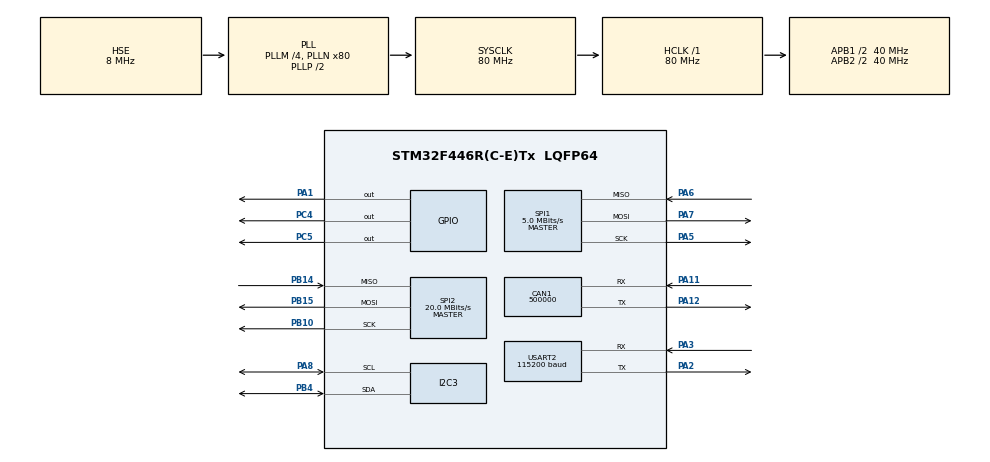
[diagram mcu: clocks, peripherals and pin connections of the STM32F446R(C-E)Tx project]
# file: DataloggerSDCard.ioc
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CAN1.BS1=CAN_BS1_3TQ
CAN1.CalculateBaudRate=500000
CAN1.CalculateTimeBit=2000
CAN1.CalculateTimeQuantum=400.0
CAN1.Mode=CAN_MODE_LOOPBACK
FATFS._MAX_SS=4096
FATFS._USE_LFN=1
Mcu.Family=STM32F4
Mcu.Name=STM32F446R(C-E)Tx
Mcu.Package=LQFP64
NVIC.CAN1_RX0_IRQn=true\:0\:0\:false\:false\:true\:true\:true\:true
NVIC.CAN1_RX1_IRQn=true\:0\:0\:false\:false\:true\:true\:true\:true
NVIC.PriorityGroup=NVIC_PRIORITYGROUP_4
PA1.Signal=GPIO_Output
PA11.Mode=CAN_Activate
PA11.Signal=CAN1_RX
PA12.Mode=CAN_Activate
PA12.Signal=CAN1_TX
PA2.Mode=Asynchronous
PA2.Signal=USART2_TX
PA3.Mode=Asynchronous
PA3.Signal=USART2_RX
PA5.Mode=Full_Duplex_Master
PA5.Signal=SPI1_SCK
PA6.Mode=Full_Duplex_Master
PA6.Signal=SPI1_MISO
PA7.Mode=Full_Duplex_Master
PA7.Signal=SPI1_MOSI
PA8.Mode=I2C
PA8.Signal=I2C3_SCL
PB10.Mode=Full_Duplex_Master
PB10.Signal=SPI2_SCK
PB14.Mode=Full_Duplex_Master
PB14.Signal=SPI2_MISO
PB15.Mode=Full_Duplex_Master
PB15.Signal=SPI2_MOSI
PB4.Mode=I2C
PB4.Signal=I2C3_SDA
PC4.GPIO_Speed=GPIO_SPEED_FREQ_MEDIUM
PC4.PinState=GPIO_PIN_SET
PC4.Signal=GPIO_Output
PC5.Signal=GPIO_Output
PH0-OSC_IN.Mode=HSE-External-Oscillator
PH0-OSC_IN.Signal=RCC_OSC_IN
PH1-OSC_OUT.Mode=HSE-External-Oscillator
PH1-OSC_OUT.Signal=RCC_OSC_OUT
ProjectManager.HeapSize=0x400
ProjectManager.StackSize=0x400
ProjectManager.TargetToolchain=STM32CubeIDE
RCC.AHBFreq_Value=80000000
RCC.APB1CLKDivider=RCC_HCLK_DIV2
RCC.APB1Freq_Value=40000000
RCC.APB1TimFreq_Value=80000000
RCC.APB2CLKDivider=RCC_HCLK_DIV2
RCC.APB2Freq_Value=40000000
RCC.APB2TimFreq_Value=80000000
RCC.CortexFreq_Value=80000000
RCC.HCLKFreq_Value=80000000
RCC.HSE_VALUE=8000000
RCC.PLLM=4
RCC.PLLN=80
RCC.PLLSourceVirtual=RCC_PLLSOURCE_HSE
RCC.SYSCLKFreq_VALUE=80000000
RCC.SYSCLKSource=RCC_SYSCLKSOURCE_PLLCLK
RCC.USBFreq_Value=80000000
RCC.VCOOutputFreq_Value=160000000
SPI1.BaudRatePrescaler=SPI_BAUDRATEPRESCALER_8
SPI1.CalculateBaudRate=5.0 MBits/s
SPI1.Direction=SPI_DIRECTION_2LINES
SPI1.Mode=SPI_MODE_MASTER
SPI1.VirtualType=VM_MASTER
SPI2.CalculateBaudRate=20.0 MBits/s
SPI2.Direction=SPI_DIRECTION_2LINES
SPI2.Mode=SPI_MODE_MASTER
SPI2.VirtualType=VM_MASTER
USART2.BaudRate=115200
USART2.VirtualMode=VM_ASYNC
VP_FATFS_VS_Generic.Mode=User_defined
board=custom

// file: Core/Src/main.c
/* USER CODE BEGIN Header */
/**
  ******************************************************************************
  * @file           : main.c
  * @brief          : Main program body
  ******************************************************************************
  * @attention
  *
  * Copyright (c) 2023 STMicroelectronics.
  * All rights reserved.
  *
  * This software is licensed under terms that can be found in the LICENSE file
  * in the root directory of this software component.
  * If no LICENSE file comes with this software, it is provided AS-IS.
  *
  *
  *SD CARD PINOUTS
  *SCK - PA5
  *MISO - PA6
  *MOSI - PA7
  *CS - PC4
  *CAN TX - PA12
  *CAN RX - PA11
  ******************************************************************************
  */
/* USER CODE END Header */
#include "main.h"
#include "fatfs.h"

/* USER CODE BEGIN Includes */
#include <string.h>
#include <stdio.h>
/* USER CODE END Includes */

CAN_HandleTypeDef hcan1;

I2C_HandleTypeDef hi2c3;

SPI_HandleTypeDef hspi1;
SPI_HandleTypeDef hspi2;

UART_HandleTypeDef huart2;

void SystemClock_Config(void);
static void MX_GPIO_Init(void);
static void MX_SPI1_Init(void);
static void MX_USART2_UART_Init(void);
static void MX_CAN1_Init(void);
static void MX_I2C3_Init(void);
static void MX_SPI2_Init(void);

/* USER CODE BEGIN 0 */

circBuffer FEBBuffer;
/* USER CODE END 0 */

int main(void)
{

  /* MCU Configuration--------------------------------------------------------*/

  /* Reset of all peripherals, Initializes the Flash interface and the Systick. */
  HAL_Init();

  /* Configure the system clock */
  SystemClock_Config();

  /* Initialize all configured peripherals */
  MX_GPIO_Init();
  MX_SPI1_Init();
  MX_FATFS_Init();
  MX_USART2_UART_Init();
  MX_CAN1_Init();
  MX_I2C3_Init();
  MX_SPI2_Init();
  /* USER CODE BEGIN 2 */

  FEB_circBuf_init(&FEBBuffer);

//  fres = f_mount(&fs, "", 0);
//  if (fres != FR_OK) send_uart ("error in mounting SD Card...\n");
//  else send_uart("SD Card mounted successfully...");
//
//
//  totalSpace = (uint32_t)((pfs->n_fatent - 2) * pfs->csize * 0.5);
//  sprintf (buffer, "SD CARD Total Size: \t%lu\n", totalSpace);
//  send_uart(buffer);
//  bufclear();
//  freeSpace = (uint32_t)(fre_clust * pfs->csize * 0.5);
//  sprintf (buffer, "SD CARD Free Space: \t%lu\n",freeSpace);
//  send_uart(buffer);
//
//  //Open file to write/create a file it doesn't exist
//  fres = f_open(&fil, "test.txt", FA_OPEN_ALWAYS | FA_READ | FA_WRITE);

  // Writing text
  //fres = f_puts("This data is from the First FILE\n\n", &fil);

  //send_uart ("File1.txt created and the data is written \n");

  //Close file
  //fres = f_close(&fil);

 //Open file to read
  //fres = f_open(&fil, "file1.txt", FA_READ);

  //Read string from the file
  //f_gets(buffer, sizeof(buffer), &fil);

  //send_uart(buffer);

  //Close file
  //f_close(&fil);

//  bufclear();

  /* UART testing */
//  uint8_t data[20] ="transmitted";

//  FEB_circBuf_init(FEBBuffer);
  //uint8_t bytesToWrite = strlen(FEBBuffer);
  //uint8_t bytesToWriten;

  //FEB_circBuf_write(FEBBuffer, "hello\n");
  //FEB_circBuf_write(FEBBuffer,"world\n");

  FEB_CAN_Init();
  FEB_BNO085_Setup();
  // uint32_t testID = 0x32;
  // uint8_t random_buffer[] = {0x02, 0x15, 0x23, 0x44, 0x11, 0x22, 0x33, 0x44};
  // FEB_circBuf_write(&FEBBuffer, testID, random_buffer);
  // FEB_circBuf_read(&FEBBuffer);

  /* USER CODE END 2 */

  /* Infinite loop */
  /* USER CODE BEGIN WHILE */
  while (1)
  {

	  /*FEB_circBuf_write(FEBBuffer, "hello\n");

	  FEB_circBuf_write(FEBBuffer,"world\n");

	  char* lastRead = FEB_circBuf_read(FEBBuffer);
	  f_puts(lastRead, &fil);

	  //Hopefully frees up the section in the circularBuffer
	  free(lastRead);
	  FEBBuffer->read = (FEBBuffer->read + 1) % FEBBuffer->capacity;
	  FEBBuffer->count--;
	  //f_write(&fil, FEBBuffer, bytesToWrite, bytesToWriten);
	  f_sync(&fil);
	  send_uart ("File1.txt created and the data is written \n");

	  lastRead = FEB_circBuf_read(FEBBuffer);
	  f_puts(lastRead, &fil);

	  //Hopefully frees up the section in the circularBuffer
	  free(lastRead);
	  FEBBuffer->read = (FEBBuffer->read + 1) % FEBBuffer->capacity;
	  FEBBuffer->count--;
	  //f_write(&fil, FEBBuffer, bytesToWrite, bytesToWriten);
	  f_sync(&fil);
	  send_uart ("File1.txt created and the data is written \n");
	  */
//	  float transmit_data = 0;
//	  FEB_CAN_Transmit_Test_Float(&hcan1,transmit_data);
//
//	  char* lastRead = FEB_circBuf_read(FEBBuffer);
//	  strcat(lastRead, '\0');
//	  f_puts(lastRead, &fil);
//
//	  //Hopefully frees up the section in the circularBuffer
//	  free(lastRead);
//	  FEBBuffer->read = (FEBBuffer->read + 1) % FEBBuffer->capacity;
//	  FEBBuffer->count--;
//	  //f_write(&fil, FEBBuffer, bytesToWrite, bytesToWriten);
//	  f_sync(&fil);
//	  HAL_UART_Transmit(&huart2, data, strlen((char*)data), HAL_MAX_DELAY);
//	  HAL_Delay(10);

//	  transmit_data = transmit_data + 0.5;
	FEB_CAN_Transmit_Test_Data(&hcan1);
    FEB_CAN_Transmit_Test_Data_ExtId(&hcan1);
    FEB_BNO085_Poll(&hi2c3);
    FEB_circBuf_read(&FEBBuffer);
    FEB_circBuf_read(&FEBBuffer);
	HAL_Delay(200);

    /* USER CODE END WHILE */

  }
}

void SystemClock_Config(void)
{
  RCC_OscInitTypeDef RCC_OscInitStruct = {0};
  RCC_ClkInitTypeDef RCC_ClkInitStruct = {0};

  /** Configure the main internal regulator output voltage
  */
  __HAL_RCC_PWR_CLK_ENABLE();
  __HAL_PWR_VOLTAGESCALING_CONFIG(PWR_REGULATOR_VOLTAGE_SCALE3);

  /** Initializes the RCC Oscillators according to the specified parameters
  * in the RCC_OscInitTypeDef structure.
  */
  RCC_OscInitStruct.OscillatorType = RCC_OSCILLATORTYPE_HSE;
  RCC_OscInitStruct.HSEState = RCC_HSE_ON;
  RCC_OscInitStruct.PLL.PLLState = RCC_PLL_ON;
  RCC_OscInitStruct.PLL.PLLSource = RCC_PLLSOURCE_HSE;
  RCC_OscInitStruct.PLL.PLLM = 4;
  RCC_OscInitStruct.PLL.PLLN = 80;
  RCC_OscInitStruct.PLL.PLLP = RCC_PLLP_DIV2;
  RCC_OscInitStruct.PLL.PLLQ = 2;
  RCC_OscInitStruct.PLL.PLLR = 2;
  if (HAL_RCC_OscConfig(&RCC_OscInitStruct) != HAL_OK)
  {
    Error_Handler();
  }

  /** Initializes the CPU, AHB and APB buses clocks
  */
  RCC_ClkInitStruct.ClockType = RCC_CLOCKTYPE_HCLK|RCC_CLOCKTYPE_SYSCLK
                              |RCC_CLOCKTYPE_PCLK1|RCC_CLOCKTYPE_PCLK2;
  RCC_ClkInitStruct.SYSCLKSource = RCC_SYSCLKSOURCE_PLLCLK;
  RCC_ClkInitStruct.AHBCLKDivider = RCC_SYSCLK_DIV1;
  RCC_ClkInitStruct.APB1CLKDivider = RCC_HCLK_DIV2;
  RCC_ClkInitStruct.APB2CLKDivider = RCC_HCLK_DIV2;

  if (HAL_RCC_ClockConfig(&RCC_ClkInitStruct, FLASH_LATENCY_2) != HAL_OK)
  {
    Error_Handler();
  }
}

static void MX_CAN1_Init(void)
{

  hcan1.Instance = CAN1;
  hcan1.Init.Prescaler = 16;
  hcan1.Init.Mode = CAN_MODE_LOOPBACK;
  hcan1.Init.SyncJumpWidth = CAN_SJW_1TQ;
  hcan1.Init.TimeSeg1 = CAN_BS1_3TQ;
  hcan1.Init.TimeSeg2 = CAN_BS2_1TQ;
  hcan1.Init.TimeTriggeredMode = DISABLE;
  hcan1.Init.AutoBusOff = DISABLE;
  hcan1.Init.AutoWakeUp = DISABLE;
  hcan1.Init.AutoRetransmission = DISABLE;
  hcan1.Init.ReceiveFifoLocked = DISABLE;
  hcan1.Init.TransmitFifoPriority = DISABLE;
  if (HAL_CAN_Init(&hcan1) != HAL_OK)
  {
    Error_Handler();
  }

}

static void MX_I2C3_Init(void)
{

  hi2c3.Instance = I2C3;
  hi2c3.Init.ClockSpeed = 100000;
  hi2c3.Init.DutyCycle = I2C_DUTYCYCLE_2;
  hi2c3.Init.OwnAddress1 = 0;
  hi2c3.Init.AddressingMode = I2C_ADDRESSINGMODE_7BIT;
  hi2c3.Init.DualAddressMode = I2C_DUALADDRESS_DISABLE;
  hi2c3.Init.OwnAddress2 = 0;
  hi2c3.Init.GeneralCallMode = I2C_GENERALCALL_DISABLE;
  hi2c3.Init.NoStretchMode = I2C_NOSTRETCH_DISABLE;
  if (HAL_I2C_Init(&hi2c3) != HAL_OK)
  {
    Error_Handler();
  }

}

static void MX_SPI1_Init(void)
{

  /* SPI1 parameter configuration*/
  hspi1.Instance = SPI1;
  hspi1.Init.Mode = SPI_MODE_MASTER;
  hspi1.Init.Direction = SPI_DIRECTION_2LINES;
  hspi1.Init.DataSize = SPI_DATASIZE_8BIT;
  hspi1.Init.CLKPolarity = SPI_POLARITY_LOW;
  hspi1.Init.CLKPhase = SPI_PHASE_1EDGE;
  hspi1.Init.NSS = SPI_NSS_SOFT;
  hspi1.Init.BaudRatePrescaler = SPI_BAUDRATEPRESCALER_8;
  hspi1.Init.FirstBit = SPI_FIRSTBIT_MSB;
  hspi1.Init.TIMode = SPI_TIMODE_DISABLE;
  hspi1.Init.CRCCalculation = SPI_CRCCALCULATION_DISABLE;
  hspi1.Init.CRCPolynomial = 10;
  if (HAL_SPI_Init(&hspi1) != HAL_OK)
  {
    Error_Handler();
  }

}

static void MX_SPI2_Init(void)
{

  /* SPI2 parameter configuration*/
  hspi2.Instance = SPI2;
  hspi2.Init.Mode = SPI_MODE_MASTER;
  hspi2.Init.Direction = SPI_DIRECTION_2LINES;
  hspi2.Init.DataSize = SPI_DATASIZE_8BIT;
  hspi2.Init.CLKPolarity = SPI_POLARITY_LOW;
  hspi2.Init.CLKPhase = SPI_PHASE_1EDGE;
  hspi2.Init.NSS = SPI_NSS_SOFT;
  hspi2.Init.BaudRatePrescaler = SPI_BAUDRATEPRESCALER_2;
  hspi2.Init.FirstBit = SPI_FIRSTBIT_MSB;
  hspi2.Init.TIMode = SPI_TIMODE_DISABLE;
  hspi2.Init.CRCCalculation = SPI_CRCCALCULATION_DISABLE;
  hspi2.Init.CRCPolynomial = 10;
  if (HAL_SPI_Init(&hspi2) != HAL_OK)
  {
    Error_Handler();
  }

}

static void MX_USART2_UART_Init(void)
{

  huart2.Instance = USART2;
  huart2.Init.BaudRate = 115200;
  huart2.Init.WordLength = UART_WORDLENGTH_8B;
  huart2.Init.StopBits = UART_STOPBITS_1;
  huart2.Init.Parity = UART_PARITY_NONE;
  huart2.Init.Mode = UART_MODE_TX_RX;
  huart2.Init.HwFlowCtl = UART_HWCONTROL_NONE;
  huart2.Init.OverSampling = UART_OVERSAMPLING_16;
  if (HAL_UART_Init(&huart2) != HAL_OK)
  {
    Error_Handler();
  }

}

static void MX_GPIO_Init(void)
{
  GPIO_InitTypeDef GPIO_InitStruct = {0};

  /* GPIO Ports Clock Enable */
  __HAL_RCC_GPIOH_CLK_ENABLE();
  __HAL_RCC_GPIOA_CLK_ENABLE();
  __HAL_RCC_GPIOC_CLK_ENABLE();
  __HAL_RCC_GPIOB_CLK_ENABLE();

  /*Configure GPIO pin Output Level */
  HAL_GPIO_WritePin(GPIOA, GPIO_PIN_1, GPIO_PIN_RESET);

  /*Configure GPIO pin Output Level */
  HAL_GPIO_WritePin(GPIOC, GPIO_PIN_4, GPIO_PIN_SET);

  /*Configure GPIO pin Output Level */
  HAL_GPIO_WritePin(GPIOC, GPIO_PIN_5, GPIO_PIN_RESET);

  /*Configure GPIO pin : PA1 */
  GPIO_InitStruct.Pin = GPIO_PIN_1;
  GPIO_InitStruct.Mode = GPIO_MODE_OUTPUT_PP;
  GPIO_InitStruct.Pull = GPIO_NOPULL;
  GPIO_InitStruct.Speed = GPIO_SPEED_FREQ_LOW;
  HAL_GPIO_Init(GPIOA, &GPIO_InitStruct);

  /*Configure GPIO pin : PC4 */
  GPIO_InitStruct.Pin = GPIO_PIN_4;
  GPIO_InitStruct.Mode = GPIO_MODE_OUTPUT_PP;
  GPIO_InitStruct.Pull = GPIO_NOPULL;
  GPIO_InitStruct.Speed = GPIO_SPEED_FREQ_MEDIUM;
  HAL_GPIO_Init(GPIOC, &GPIO_InitStruct);

  /*Configure GPIO pin : PC5 */
  GPIO_InitStruct.Pin = GPIO_PIN_5;
  GPIO_InitStruct.Mode = GPIO_MODE_OUTPUT_PP;
  GPIO_InitStruct.Pull = GPIO_NOPULL;
  GPIO_InitStruct.Speed = GPIO_SPEED_FREQ_LOW;
  HAL_GPIO_Init(GPIOC, &GPIO_InitStruct);

}

void Error_Handler(void)
{
  __disable_irq();
  while (1)
  {
  }
}
